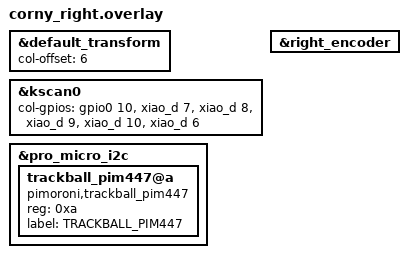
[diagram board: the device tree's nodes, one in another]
#include "corny.dtsi"

&default_transform {
    col-offset = <6>;
};

&kscan0 {
    col-gpios
        = <&gpio0 10 GPIO_ACTIVE_HIGH>
        , <&xiao_d 7 GPIO_ACTIVE_HIGH>
        , <&xiao_d 8 GPIO_ACTIVE_HIGH>
        , <&xiao_d 9 GPIO_ACTIVE_HIGH>
        , <&xiao_d 10 GPIO_ACTIVE_HIGH>
        , <&xiao_d 6 GPIO_ACTIVE_HIGH>
        ;
};

&right_encoder {
    status = "okay";
};

# see: https://github.com/cdc-mkb/zmk/commit/eb8889883d1e91f58a42f0babc17a10fa3fa1b4a#diff-37aef75709242f012d17c7efe6b1ae3bdeecd5560fab5bf05269cd0b6d44c356
&pro_micro_i2c {
	status = "okay";
	trackball_pim447@a {
		compatible = "pimoroni,trackball_pim447";
		reg = <0xa>;
		label = "TRACKBALL_PIM447";
	};
};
